# STM32H723 register map
File version: 1.6
CPU: CM7 r0p1, little endian, MPU, FPU, 4 interrupt priority bits
Registers are 32-bit, read-write, reset 0x0 unless marked. A register's access mark holds for its fields unless they carry their own. Offsets are from the block's base; [hi:lo] are bit positions; lines under a group give offsets from that group; {n}, {i} and the like mark numbered series; 'fields as' and 'values as' point back to an identical list.

## ADC1 (part 2 of 2) — Analog to Digital Converter
Base 0x40022000
Same registers: ADC2 0x40022100
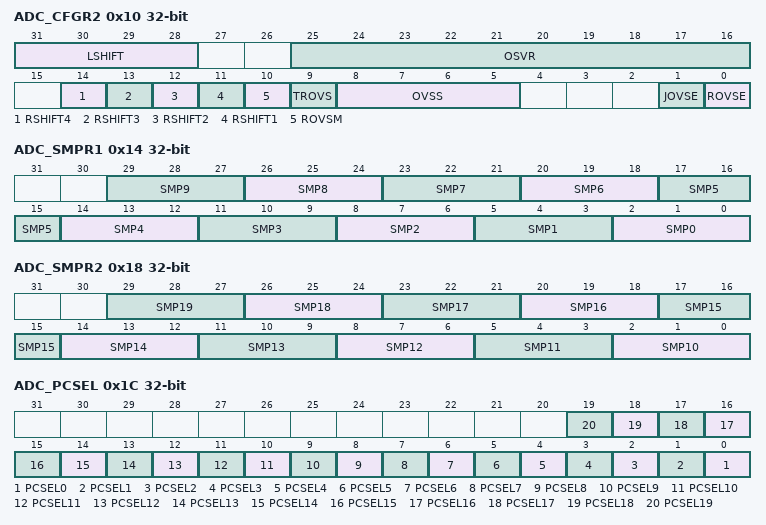
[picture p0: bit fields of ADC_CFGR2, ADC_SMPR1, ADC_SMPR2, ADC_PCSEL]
0x10 ADC_CFGR2 — ADC configuration register 2
  [31:28] LSHIFT — Left shift factor This bitfield is set and cleared by software to define the left shifting applied to the final result with or without oversampling. Note: The software is allowed to write this bit only when ADSTART=0 (which ensures that no conversion is ongoing).
    0=No left shift; 1=Shift left 1-bit; {v}=Shift left {v}-bits (v=2..15)
  [25:16] OSVR — Oversampling ratio This bitfield is set and cleared by software to define the oversampling ratio. 2: 3x ... 1023: 1024x Note: The software is allowed to write this bit only when ADSTART=0 (which ensures that no conversion is ongoing).
    0=1x (no oversampling); 1=2x
  [14] RSHIFT4 — Right-shift data after Offset 4 correction Refer to RSHIFT1 description.
  [13] RSHIFT3 — Right-shift data after Offset 3 correction Refer to RSHIFT1 description
  [12] RSHIFT2 — Right-shift data after Offset 2 correction Refer to RSHIFT1 description
  [11] RSHIFT1 — Right-shift data after Offset 1 correction This bitfield is set and cleared by software to right-shift 1-bit data after offset1 correction. This bit can only be used for 8-bit and 16-bit data format (see (ADC_DR, ADC_JDRy, OFFSETy, OFFSETy_CH, OVSS, LSHIFT, RSHIFT, SSATE) for details).
    0=Right-shifting disabled; 1=Data is right-shifted 1-bit
  [10] ROVSM — Regular Oversampling mode This bit is set and cleared by software to select the regular oversampling mode. Note: The software is allowed to write this bit only when ADSTART=0 (which ensures that no conversion is ongoing).
    0=Continued mode: When injected conversions are triggered, the oversampling is temporary stopped and continued after the injection sequence (oversampling buffer is maintained during injected sequence); 1=Resumed mode: When injected conversions are triggered, the current oversampling is aborted and resumed from start after the injection sequence (oversampling buffer is zeroed by injected sequence start)
  [9] TROVS — Triggered Regular Oversampling This bit is set and cleared by software to enable triggered oversampling Note: The software is allowed to write this bit only when ADSTART=0 (which ensures that no conversion is ongoing).
    0=All oversampled conversions for a channel are done consecutively following a trigger; 1=Each oversampled conversion for a channel needs a new trigger
  [8:5] OVSS — Oversampling right shift This bitfield is set and cleared by software to define the right shifting applied to the raw oversampling result. Others: Reserved, must not be used. Note: The software is allowed to write these bits only when ADSTART=0 (which ensures that no conversion is ongoing).
    0=No right shift; 1=Shift right 1-bit; {v}=Shift right {v}-bits (v=2..11)
  [1] JOVSE — Injected Oversampling Enable This bit is set and cleared by software to enable injected oversampling. Note: The software is allowed to write this bit only when ADSTART=0 and JADSTART=0 (which ensures that no conversion is ongoing)
    0=Injected Oversampling disabled; 1=Injected Oversampling enabled
  [0] ROVSE — Regular Oversampling Enable This bit is set and cleared by software to enable regular oversampling. Note: The software is allowed to write this bit only when ADSTART=0 and JADSTART=0 (which ensures that no conversion is ongoing)
    0=Regular Oversampling disabled; 1=Regular Oversampling enabled
0x14 ADC_SMPR1 — ADC sample time register 1
  [all] fields
    0=1.5 ADC clock cycles; 1=2.5 ADC clock cycles; 2=8.5 ADC clock cycles; 3=16.5 ADC clock cycles; 4=32.5 ADC clock cycles; 5=64.5 ADC clock cycles; 6=387.5 ADC clock cycles; 7=810.5 ADC clock cycles
  [3n+2:3n] SMP{n} (n=0..9) — Channel x sampling time selection (x = 0 to 9) These bits are written by software to select the sampling time individually for each channel. During sample cycles, the channel selection bits must remain unchanged. Note: The software is allowed to write these bits only when ADSTART=0 and JADSTART=0 (which ensures that no conversion is ongoing).
0x18 ADC_SMPR2 — ADC sample time register 2
  [all] fields
    values as the fields of ADC_SMPR1
  [3n-28:3n-30] SMP{n} (n=10..19) — Channel x sampling time selection (x = 10 to 19) These bits are written by software to select the sampling time individually for each channel. During sampling cycles, the channel selection bits must remain unchanged. Note: The software is allowed to write these bits only when ADSTART=0 and JADSTART=0 (which ensures that no conversion is ongoing).
0x1C ADC_PCSEL — ADC channel preselection register
  [all] fields
    0=Input Channel x (Vinp x) is not pre selected for conversion, the ADC conversion result with this channel shows wrong result; 1=Input Channel x (Vinp x) is pre selected for conversion
  [n] PCSEL{n} (n=0..19) — :Channel x (VINP[i]) pre selection (x = 0 to 19) These bits are written by software to pre select the input channel at IO instance to be converted. Note: The software is allowed to write these bits only when ADSTART=0 and JADSTART=0 (which ensures that no conversion is ongoing).
0x20 ADC_LTR1 — ADC watchdog threshold register 1
  [25:0] LTR1 — Analog watchdog 1 lower threshold These bits are written by software to define the lower threshold for the analog watchdog 1. Refer to AWD2CH, AWD3CH, AWD_HTRy, AWD_LTRy, AWDy) Note: The software is allowed to write these bits only when ADSTART=0 and JADSTART=0 (which ensures that no conversion is ongoing).
0x24 ADC_HTR1 reset 0x3FFFFFF — ADC watchdog threshold register 1
  [25:0] HTR1 — Analog watchdog 1 higher threshold These bits are written by software to define the higher threshold for the analog watchdog 1. Refer to AWD2CH, AWD3CH, AWD_HTRy, AWD_LTRy, AWDy) Note: The software is allowed to write these bits only when ADSTART=0 and JADSTART=0 (which ensures that no conversion is ongoing).
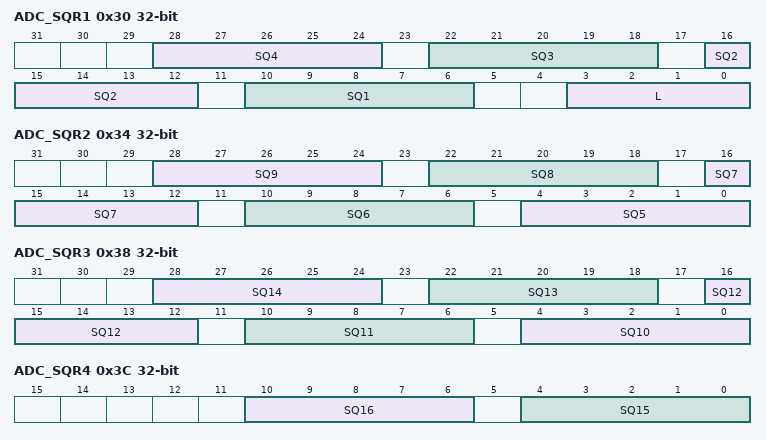
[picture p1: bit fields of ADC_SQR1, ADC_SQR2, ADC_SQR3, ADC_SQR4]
0x30 ADC_SQR1 — ADC regular sequence register 1
  [28:24] SQ4 — 4th conversion in regular sequence These bits are written by software with the channel number (0..19) assigned as the 4th in the regular conversion sequence.
  [22:18] SQ3 — 3rd conversion in regular sequence These bits are written by software with the channel number (0..19) assigned as the 3rd in the regular conversion sequence. Note: The software is allowed to write these bits only when ADSTART=0 (which ensures that no regular conversion is ongoing).
  [16:12] SQ2 — 2nd conversion in regular sequence These bits are written by software with the channel number (0..19) assigned as the 2nd in the regular conversion sequence. Note: The software is allowed to write these bits only when ADSTART=0 (which ensures that no regular conversion is ongoing).
  [10:6] SQ1 — 1st conversion in regular sequence These bits are written by software with the channel number (0..19) assigned as the 1st in the regular conversion sequence. Note: The software is allowed to write these bits only when ADSTART=0 (which ensures that no regular conversion is ongoing).
  [3:0] L — Regular channel sequence length These bits are written by software to define the total number of conversions in the regular channel conversion sequence. ... Note: The software is allowed to write these bits only when ADSTART=0 (which ensures that no regular conversion is ongoing).
    0=1 conversion; 1=2 conversions; 15=16 conversions
0x34 ADC_SQR2 — ADC regular sequence register 2
  [28:24] SQ9 — 9th conversion in regular sequence These bits are written by software with the channel number (0..19) assigned as the 9th in the regular conversion sequence. Note: The software is allowed to write these bits only when ADSTART=0 (which ensures that no regular conversion is ongoing).
  [22:18] SQ8 — 8th conversion in regular sequence These bits are written by software with the channel number (0..19) assigned as the 8th in the regular conversion sequence Note: The software is allowed to write these bits only when ADSTART=0 (which ensures that no regular conversion is ongoing).
  [16:12] SQ7 — 7th conversion in regular sequence These bits are written by software with the channel number (0..19) assigned as the 7th in the regular conversion sequence. Note: The software is allowed to write these bits only when ADSTART=0 (which ensures that no regular conversion is ongoing).
  [10:6] SQ6 — 6th conversion in regular sequence These bits are written by software with the channel number (0..19) assigned as the 6th in the regular conversion sequence. Note: The software is allowed to write these bits only when ADSTART=0 (which ensures that no regular conversion is ongoing).
  [4:0] SQ5 — 5th conversion in regular sequence These bits are written by software with the channel number (0..19) assigned as the 5th in the regular conversion sequence. Note: The software is allowed to write these bits only when ADSTART=0 (which ensures that no regular conversion is ongoing).
0x38 ADC_SQR3 — ADC regular sequence register 3
  [6n-56:6n-60] SQ{n} (n=10..14) — {n}th conversion in regular sequence These bits are written by software with the channel number (0..19) assigned as the {n}th in the regular conversion sequence. Note: The software is allowed to write these bits only when ADSTART=0 (which ensures that no regular conversion is ongoing).
0x3C ADC_SQR4 — ADC regular sequence register 4
  [10:6] SQ16 — 16th conversion in regular sequence These bits are written by software with the channel number (0..19) assigned as the 16th in the regular conversion sequence. Note: The software is allowed to write these bits only when ADSTART=0 (which ensures that no regular conversion is ongoing).
  [4:0] SQ15 — 15th conversion in regular sequence These bits are written by software with the channel number (0..19) assigned as the 15th in the regular conversion sequence. Note: The software is allowed to write these bits only when ADSTART=0 (which ensures that no regular conversion is ongoing).
0x40 ADC_DR ro — ADC regular Data Register
  [31:0] RDATA — Regular Data converted These bits are read-only. They contain the conversion result from the last converted regular channel. The data are left- or right-aligned as described in .
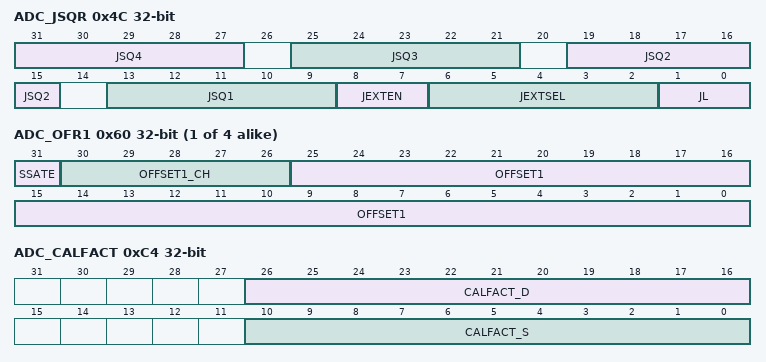
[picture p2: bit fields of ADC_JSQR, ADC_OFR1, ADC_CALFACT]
0x4C ADC_JSQR — ADC injected sequence register
  [31:27] JSQ4 — 4th conversion in the injected sequence These bits are written by software with the channel number (0..19) assigned as the 4th in the injected conversion sequence. Note: The software is allowed to write these bits only when JADSTART is cleared to 0 (no injected conversion is ongoing) unless the context queue is enabled (JQDIS=0 in ADC_CFGR register).
  [25:21] JSQ3 — 3rd conversion in the injected sequence These bits are written by software with the channel number (0..19) assigned as the 3rd in the injected conversion sequence. Note: The software is allowed to write these bits only when JADSTART is cleared to 0 (no injected conversion is ongoing) unless the context queue is enabled (JQDIS=0 in ADC_CFGR register).
  [19:15] JSQ2 — 2nd conversion in the injected sequence These bits are written by software with the channel number (0..19) assigned as the 2nd in the injected conversion sequence. Note: The software is allowed to write these bits only when JADSTART is cleared to 0 (no injected conversion is ongoing) unless the context queue is enabled (JQDIS=0 in ADC_CFGR register).
  [13:9] JSQ1 — 1st conversion in the injected sequence These bits are written by software with the channel number (0..19) assigned as the 1st in the injected conversion sequence. Note: The software is allowed to write these bits only when JADSTART is cleared to 0 (no injected conversion is ongoing) unless the context queue is enabled (JQDIS=0 in ADC_CFGR register).
  [8:7] JEXTEN — External trigger enable and polarity selection for injected channels These bits are set and cleared by software to select the external trigger polarity and enable the trigger of an injected group. If JQDIS=1 (queue disabled), Hardware trigger detection disabled (conversions can be launched by software Note: The software is allowed to write these bits only when JADSTART is cleared to 0 (no injected conversion is ongoing). If JQM=1 and if the Queue of Context becomes empty, the software and hardware triggers of the injected sequence are both internally disabled (refer to Queue of context for injected conversions)
    0=If JQDIS=0 (queue enabled), Hardware and software trigger detection disabled and; 1=Hardware trigger detection on the rising edge; 2=Hardware trigger detection on the falling edge; 3=Hardware trigger detection on both the rising and falling edges
  [6:2] JEXTSEL — External trigger selection for injected group These bits select the external event used to trigger the start of conversion of an injected group: ... Note: The software is allowed to write these bits only when JADSTART is cleared to 0 (no injected conversion is ongoing).
    {v}=Event {v} (v=0..7); 31=Event 31:
  [1:0] JL — Injected channel sequence length These bits are written by software to define the total number of conversions in the injected channel conversion sequence. Note: The software is allowed to write these bits only when JADSTART is cleared to 0 (no injected conversion is ongoing).
    0=1 conversion; 1=2 conversions; 2=3 conversions; 3=4 conversions
{0x5C+4i} ADC_OFR{i} (i=1..4) — ADC injected channel {i} offset register
  [31] SSATE — Signed saturation Enable This bit is written by software to enable or disable the Signed saturation feature. This bit can be enabled only for 8-bit and 16-bit data format (see alignment and offset (ADC_DR, ADC_JDRy, OFFSETy, OFFSETy_CH, OVSS, LSHIFT, RSHIFT, SSATE) for details). Note: The software is allowed to write this bit only when ADSTART=0 and JADSTART=0 (which ensures that no conversion is ongoing).
    0=Offset is subtracted maintaining data integrity and extending result size (9-bit and 17-bit signed format); 1=Offset is subtracted and result is saturated to maintain result size
  [30:26] OFFSET{i}_CH — Channel selection for the Data offset y These bits are written by software to define the channel to which the offset programmed into bits OFFSETy[25:0] will apply. Note: The software is allowed to write these bits only when ADSTART=0 and JADSTART=0 (which ensures that no conversion is ongoing).
  [25:0] OFFSET{i} — Data offset y for the channel programmed into bits OFFSETy_CH[4:0] These bits are written by software to define the offset y to be subtracted from the raw converted data when converting a channel (can be regular or injected). The channel to which applies the data offset y must be programmed in the bits OFFSETy_CH[4:0]. The conversion result can be read from in the ADC_DR (regular conversion) or from in the ADC_JDRyi registers (injected conversion). When OFFSETy[25:0] bitfield is reset, the offset compensation is disabled. Note: The software is allowed to write these bits only when ADSTART=0 and JADSTART=0 (which ensures that no conversion is ongoing). If several offset (OFFSETy) point to the same channel, only the offset with the lowest x value is considered for the subtraction. Ex: if OFFSET1_CH[4:0]=4 and OFFSET2_CH[4:0]=4, this is OFFSET1[25:0] which is subtracted when converting channel 4.
{0x7C+4i} ADC_JDR{i} ro (i=1..4) — ADC injected channel {i} data register
  [31:0] JDATA — Injected data These bits are read-only. They contain the conversion result from injected channel y. The data are left -or right-aligned as described in .
0xA0 ADC_AWD2CR — ADC analog watchdog 2 configuration register
  [19:0] AWD2CH — Analog watchdog 2 channel selection These bits are set and cleared by software. They enable and select the input channels to be guarded by the analog watchdog 2. AWD2CH[i] = 0: ADC analog input channel-i is not monitored by AWD2 AWD2CH[i] = 1: ADC analog input channel-i is monitored by AWD2 When AWD2CH[19:0] = 000..0, the analog Watchdog 2 is disabled Note: The channels selected by AWD2CH must be also selected into the SQRi or JSQRi registers. The software is allowed to write these bits only when ADSTART=0 and JADSTART=0 (which ensures that no conversion is ongoing).
0xA4 ADC_AWD3CR — ADC analog watchdog 3 configuration register
  [19:0] AWD3CH — Analog watchdog 3 channel selection These bits are set and cleared by software. They enable and select the input channels to be guarded by the analog watchdog 3. AWD3CH[i] = 0: ADC analog input channel-i is not monitored by AWD3 AWD3CH[i] = 1: ADC analog input channel-i is monitored by AWD3 When AWD3CH[19:0] = 000..0, the analog Watchdog 3 is disabled Note: The channels selected by AWD3CH must be also selected into the SQRi or JSQRi registers. The software is allowed to write these bits only when ADSTART=0 and JADSTART=0 (which ensures that no conversion is ongoing).
0xB0 ADC_LTR2 — ADC watchdog lower threshold register 2
  [25:0] LTR2 — Analog watchdog 2 lower threshold These bits are written by software to define the lower threshold for the analog watchdog 2. Refer to AWD2CH, AWD3CH, AWD_HTRy, AWD_LTRy, AWDy). Note: The software is allowed to write these bits only when ADSTART=0 and JADSTART=0 (which ensures that no conversion is ongoing).
0xB4 ADC_HTR2 reset 0x3FFFFFF — ADC watchdog higher threshold register 2
  [25:0] HTR2 — Analog watchdog 2 higher threshold These bits are written by software to define the higher threshold for the analog watchdog 2. Refer to AWD2CH, AWD3CH, AWD_HTRy, AWD_LTRy, AWDy). Note: The software is allowed to write these bits only when ADSTART=0 and JADSTART=0 (which ensures that no conversion is ongoing).
0xB8 ADC_LTR3 — ADC watchdog lower threshold register 3
  [25:0] LTR3 — Analog watchdog 3 lower threshold These bits are written by software to define the lower threshold for the analog watchdog 3. Refer to AWD2CH, AWD3CH, AWD_HTRy, AWD_LTRy, AWDy) Note: The software is allowed to write these bits only when ADSTART=0 and JADSTART=0 (which ensures that no conversion is ongoing).
0xBC ADC_HTR3 reset 0x3FFFFFF — ADC watchdog higher threshold register 3
  [25:0] HTR3 — Analog watchdog 3 higher threshold These bits are written by software to define the higher threshold for the analog watchdog 3. Refer to AWD2CH, AWD3CH, AWD_HTRy, AWD_LTRy, AWDy) Note: The software is allowed to write these bits only when ADSTART=0 and JADSTART=0 (which ensures that no conversion is ongoing).
0xC0 ADC_DIFSEL — ADC differential mode selection register
  [19:0] DIFSEL — Differential mode for channels 19 to 0 These bits are set and cleared by software. They allow to select if a channel is configured as single ended or differential mode. DIFSEL[i] = 0: ADC analog input channel-i is configured in single ended mode DIFSEL[i] = 1: ADC analog input channel-i is configured in differential mode Note: The software is allowed to write these bits only when the ADC is disabled (ADCAL=0, JADSTART=0, JADSTP=0, ADSTART=0, ADSTP=0, ADDIS=0 and ADEN=0).
0xC4 ADC_CALFACT — ADC calibration factors register
  [26:16] CALFACT_D — Calibration Factors in differential mode These bits are written by hardware or by software. Once a differential inputs calibration is complete, they are updated by hardware with the calibration factors. Software can write these bits with a new calibration factor. If the new calibration factor is different from the current one stored into the analog ADC, it will then be applied once a new differential conversion is launched. Note: The software is allowed to write these bits only when ADEN=1, ADSTART=0 and JADSTART=0 (ADC is enabled and no calibration is ongoing and no conversion is ongoing).
  [10:0] CALFACT_S — Calibration Factors In Single-Ended mode These bits are written by hardware or by software. Once a single-ended inputs calibration is complete, they are updated by hardware with the calibration factors. Software can write these bits with a new calibration factor. If the new calibration factor is different from the current one stored into the analog ADC, it will then be applied once a new single-ended conversion is launched. Note: The software is allowed to write these bits only when ADEN=1, ADSTART=0 and JADSTART=0 (ADC is enabled and no calibration is ongoing and no conversion is ongoing).
0xC8 ADC_CALFACT2 — ADC calibration factor register 2
  [29:0] LINCALFACT — Linearity Calibration Factor These bits are written by hardware or by software. They hold 30-bit out of the 160-bit linearity calibration factor. Once a single-ended inputs calibration is complete, they are updated by hardware with the calibration factors. Software can write these bits with a new calibration factor. If the new calibration factor is different from the current one stored into the analog ADC, it will then be applied once a new single-ended calibration is launched. Note: The software is allowed to write these bits only when ADEN=1, ADSTART=0 and JADSTART=0 (ADC is enabled and no calibration is ongoing and no conversion is ongoing).

## Notices in the file
Copyright (c) 2023 STMicroelectronics.
SPDX-License-Identifier: Apache-2.0
Licensed under the Apache License, Version 2.0 (the "License");
you may not use this file except in compliance with the License.
You may obtain a copy of the License at
http://www.apache.org/licenses/LICENSE-2.0
Unless required by applicable law or agreed to in writing, software
distributed under the License is distributed on an "AS IS" BASIS,
WITHOUT WARRANTIES OR CONDITIONS OF ANY KIND, either express or implied.
See the License for the specific language governing permissions and
limitations under the License.
